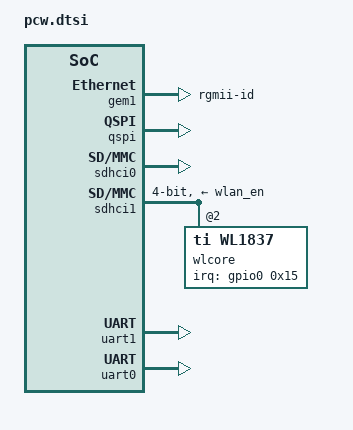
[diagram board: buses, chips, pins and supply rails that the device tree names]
/*
 * CAUTION: This file is automatically generated by Xilinx.
 * Version:  
 * Today is: Wed Jan 15 12:55:47 2020
 */


/ {
	cpus {
		cpu@0 {
			operating-points = <660000 1000000 330000 1000000>;
		};
	};
};
&gem1 {
	phy-mode = "rgmii-id";
	status = "okay";
	xlnx,ptp-enet-clock = <0x68e7780>;
};
&gpio0 {
	emio-gpio-width = <64>;
	gpio-mask-high = <0x0>;
	gpio-mask-low = <0x5600>;
};
&intc {
	num_cpus = <2>;
	num_interrupts = <96>;
};
&qspi {
	is-dual = <0>;
	num-cs = <1>;
	u-boot,dm-pre-reloc;
	status = "okay";
};
&sdhci0 {
	status = "okay";
	broken-adma2;
	xlnx,has-cd = <0x1>;
	xlnx,has-power = <0x0>;
	xlnx,has-wp = <0x1>;
};
&sdhci1 {
	status = "okay";
	broken-adma2;
	xlnx,has-cd = <0x1>;
	xlnx,has-power = <0x0>;
	xlnx,has-wp = <0x1>;
	vmmc-supply = <&wlan_en>;
	bus-width = <0x4>;
	ti,non-removable;
	ti,needs-special-hs-handling;
	cap-power-off-card;
	keep-power-in-suspend;
	#address-cells = <0x1>;
	#size-cells = <0x0>;

	wlcore@0 {
		compatible = "ti,wl1837";
		interrupt-parent = <&gpio0>;
		interrupts = <0x15 0x4>;
		reg = <0x2>;
		platform-quirks = <0x1>;
		board-ref-clock = <0x4>;
	};
};
&uart1 {
	device_type = "serial";
	port-number = <0>;
	status = "okay";
};
&uart0 {
	device_type = "serial";
	port-number = <1>;
	status = "okay";
};
&clkc {
	fclk-enable = <0x3>;
	ps-clk-frequency = <40000000>;
};
